# ATSAME70N20B register map
Vendor: Microchip Technology; Series: SAME70; File version: 0
CPU: CM7 r1p1, little endian, MPU, FPU, 3 interrupt priority bits
Registers are 32-bit, read-write, reset 0x0 unless marked. A register's access mark holds for its fields unless they carry their own. Offsets are from the block's base; [hi:lo] are bit positions; {n}, {i} and the like mark numbered series; 'fields as' and 'values as' point back to an identical list.

## USART0 — Universal Synchronous Asynchronous Receiver Transmitter
Base 0x40024000; register names take the prefix USART_
Same registers: USART1 0x40028000, USART2 0x4002C000
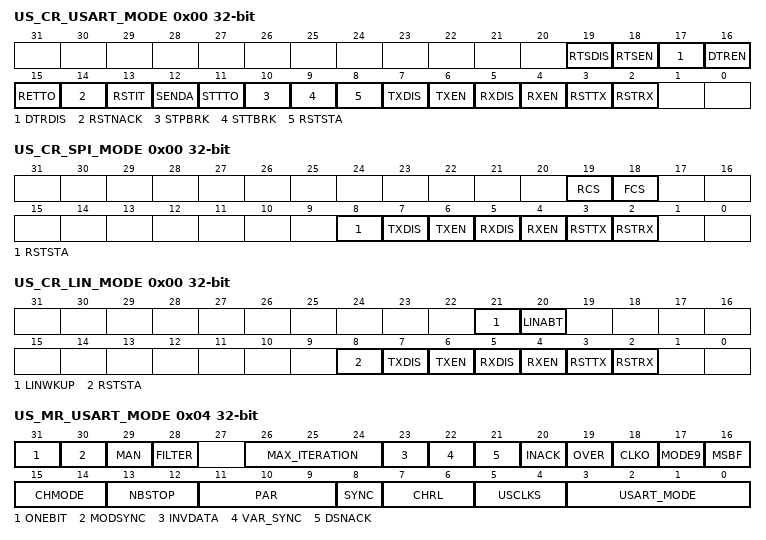
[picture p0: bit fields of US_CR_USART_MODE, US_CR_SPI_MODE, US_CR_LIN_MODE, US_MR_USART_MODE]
0x00 US_CR_USART_MODE wo — Control Register
  [19] RTSDIS — Request to Send Disable
  [18] RTSEN — Request to Send Enable
  [17] DTRDIS — Data Terminal Ready Disable
  [16] DTREN — Data Terminal Ready Enable
  [15] RETTO — Start Timeout Immediately
  [14] RSTNACK — Reset Non Acknowledge
  [13] RSTIT — Reset Iterations
  [12] SENDA — Send Address
  [11] STTTO — Clear TIMEOUT Flag and Start Timeout After Next Character Received
  [10] STPBRK — Stop Break
  [9] STTBRK — Start Break
  [8] RSTSTA — Reset Status Bits
  [7] TXDIS — Transmitter Disable
  [6] TXEN — Transmitter Enable
  [5] RXDIS — Receiver Disable
  [4] RXEN — Receiver Enable
  [3] RSTTX — Reset Transmitter
  [2] RSTRX — Reset Receiver
0x00 US_CR_SPI_MODE wo (alternate view of US_CR_USART_MODE) — Control Register
  [19] RCS — Release SPI Chip Select
  [18] FCS — Force SPI Chip Select
  [8] RSTSTA — Reset Status Bits
  [7] TXDIS — Transmitter Disable
  [6] TXEN — Transmitter Enable
  [5] RXDIS — Receiver Disable
  [4] RXEN — Receiver Enable
  [3] RSTTX — Reset Transmitter
  [2] RSTRX — Reset Receiver
0x00 US_CR_LIN_MODE wo (alternate view of US_CR_USART_MODE) — Control Register
  [21] LINWKUP — Send LIN Wakeup Signal
  [20] LINABT — Abort LIN Transmission
  [8] RSTSTA — Reset Status Bits
  [7] TXDIS — Transmitter Disable
  [6] TXEN — Transmitter Enable
  [5] RXDIS — Receiver Disable
  [4] RXEN — Receiver Enable
  [3] RSTTX — Reset Transmitter
  [2] RSTRX — Reset Receiver
0x04 US_MR_USART_MODE — Mode Register
  [31] ONEBIT — Start Frame Delimiter Selector
  [30] MODSYNC — Manchester Synchronization Mode
  [29] MAN — Manchester Encoder/Decoder Enable
  [28] FILTER — Receive Line Filter
  [26:24] MAX_ITERATION — Maximum Number of Automatic Iteration
  [23] INVDATA — Inverted Data
  [22] VAR_SYNC — Variable Synchronization of Command/Data Sync Start Frame Delimiter
  [21] DSNACK — Disable Successive NACK
  [20] INACK — Inhibit Non Acknowledge
  [19] OVER — Oversampling Mode
  [18] CLKO — Clock Output Select
  [17] MODE9 — 9-bit Character Length
  [16] MSBF — Bit Order
  [15:14] CHMODE — Channel Mode
    0=NORMAL (Normal mode); 1=AUTOMATIC (Automatic Echo. Receiver input is connected to the TXD pin.); 2=LOCAL_LOOPBACK (Local Loopback. Transmitter output is connected to the Receiver Input.); 3=REMOTE_LOOPBACK (Remote Loopback. RXD pin is internally connected to the TXD pin.)
  [13:12] NBSTOP — Number of Stop Bits
    0=_1_BIT (1 stop bit); 1=_1_5_BIT (1.5 stop bit (SYNC = 0) or reserved (SYNC = 1)); 2=_2_BIT (2 stop bits)
  [11:9] PAR — Parity Type
    0=EVEN (Even parity); 1=ODD (Odd parity); 2=SPACE (Parity forced to 0 (Space)); 3=MARK (Parity forced to 1 (Mark)); 4=NO (No parity); 6=MULTIDROP (Multidrop mode)
  [8] SYNC — Synchronous Mode Select
  [7:6] CHRL — Character Length
    {v}=_{v+5}_BIT (Character length is {v+5} bits) (v=0..3)
  [5:4] USCLKS — Clock Selection
    0=MCK (Peripheral clock is selected); 1=DIV (Peripheral clock divided (DIV = 8) is selected); 2=PCK (PMC programmable clock (PCK) is selected. If the SCK pin is driven (CLKO = 1), the CD field must be greater than 1.); 3=SCK (Serial clock (SCK) is selected)
  [3:0] USART_MODE — USART Mode of Operation
    0=NORMAL (Normal mode); 1=RS485; 2=HW_HANDSHAKING (Hardware handshaking); 3=MODEM; 4=IS07816_T_0 (IS07816 Protocol: T = 0); 6=IS07816_T_1 (IS07816 Protocol: T = 1); 8=IRDA; 9=LON; 10=LIN_MASTER (LIN Master mode); 11=LIN_SLAVE (LIN Slave mode); 14=SPI_MASTER (SPI Master mode (CLKO must be written to 1 and USCLKS = 0, 1 or 2)); 15=SPI_SLAVE (SPI Slave mode)
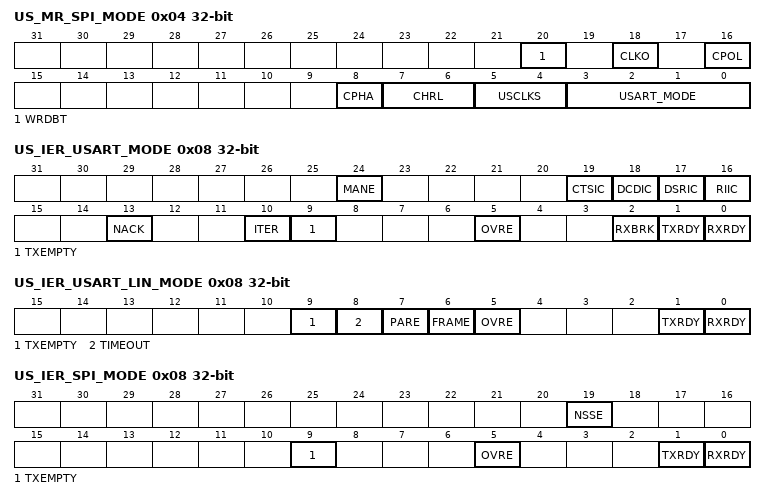
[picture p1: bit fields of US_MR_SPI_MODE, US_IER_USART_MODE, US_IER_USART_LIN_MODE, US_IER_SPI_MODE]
0x04 US_MR_SPI_MODE (alternate view of US_MR_USART_MODE) — Mode Register
  [20] WRDBT — Wait Read Data Before Transfer
  [18] CLKO — Clock Output Select
  [16] CPOL — SPI Clock Polarity
  [8] CPHA — SPI Clock Phase
  [7:6] CHRL — Character Length
    {v}=_{v+5}_BIT (Character length is {v+5} bits) (v=0..3)
  [5:4] USCLKS — Clock Selection
    values as US_MR_USART_MODE.USCLKS
  [3:0] USART_MODE — USART Mode of Operation
    values as US_MR_USART_MODE.USART_MODE
0x08 US_IER_USART_MODE wo — Interrupt Enable Register
  [24] MANE — Manchester Error Interrupt Enable
  [19] CTSIC — Clear to Send Input Change Interrupt Enable
  [18] DCDIC — Data Carrier Detect Input Change Interrupt Enable
  [17] DSRIC — Data Set Ready Input Change Enable
  [16] RIIC — Ring Indicator Input Change Enable
  [13] NACK — Non Acknowledge Interrupt Enable
  [10] ITER — Max number of Repetitions Reached Interrupt Enable
  [9] TXEMPTY — TXEMPTY Interrupt Enable
  [5] OVRE — Overrun Error Interrupt Enable
  [2] RXBRK — Receiver Break Interrupt Enable
  [1] TXRDY — TXRDY Interrupt Enable
  [0] RXRDY — RXRDY Interrupt Enable
0x08 US_IER_USART_LIN_MODE wo (alternate view of US_IER_USART_MODE) — Interrupt Enable Register
  [9] TXEMPTY — TXEMPTY Interrupt Enable
  [8] TIMEOUT — Timeout Interrupt Enable
  [7] PARE — Parity Error Interrupt Enable
  [6] FRAME — Framing Error Interrupt Enable
  [5] OVRE — Overrun Error Interrupt Enable
  [1] TXRDY — TXRDY Interrupt Enable
  [0] RXRDY — RXRDY Interrupt Enable
0x08 US_IER_SPI_MODE wo (alternate view of US_IER_USART_MODE) — Interrupt Enable Register
  [19] NSSE — NSS Line (Driving CTS Pin) Rising or Falling Edge Event
  [9] TXEMPTY — TXEMPTY Interrupt Enable
  [5] OVRE — Overrun Error Interrupt Enable
  [1] TXRDY — TXRDY Interrupt Enable
  [0] RXRDY — RXRDY Interrupt Enable
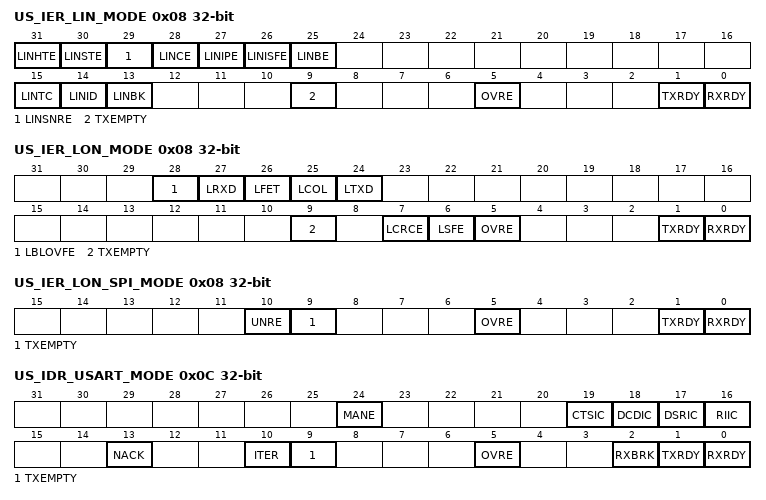
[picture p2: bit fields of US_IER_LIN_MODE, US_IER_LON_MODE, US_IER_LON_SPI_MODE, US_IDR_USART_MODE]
0x08 US_IER_LIN_MODE wo (alternate view of US_IER_USART_MODE) — Interrupt Enable Register
  [31] LINHTE — LIN Header Timeout Error Interrupt Enable
  [30] LINSTE — LIN Synch Tolerance Error Interrupt Enable
  [29] LINSNRE — LIN Slave Not Responding Error Interrupt Enable
  [28] LINCE — LIN Checksum Error Interrupt Enable
  [27] LINIPE — LIN Identifier Parity Interrupt Enable
  [26] LINISFE — LIN Inconsistent Synch Field Error Interrupt Enable
  [25] LINBE — LIN Bus Error Interrupt Enable
  [15] LINTC — LIN Transfer Completed Interrupt Enable
  [14] LINID — LIN Identifier Sent or LIN Identifier Received Interrupt Enable
  [13] LINBK — LIN Break Sent or LIN Break Received Interrupt Enable
  [9] TXEMPTY — TXEMPTY Interrupt Enable
  [5] OVRE — Overrun Error Interrupt Enable
  [1] TXRDY — TXRDY Interrupt Enable
  [0] RXRDY — RXRDY Interrupt Enable
0x08 US_IER_LON_MODE wo (alternate view of US_IER_USART_MODE) — Interrupt Enable Register
  [28] LBLOVFE — LON Backlog Overflow Error Interrupt Enable
  [27] LRXD — LON Reception Done Interrupt Enable
  [26] LFET — LON Frame Early Termination Interrupt Enable
  [25] LCOL — LON Collision Interrupt Enable
  [24] LTXD — LON Transmission Done Interrupt Enable
  [9] TXEMPTY — TXEMPTY Interrupt Enable
  [7] LCRCE — LON CRC Error Interrupt Enable
  [6] LSFE — LON Short Frame Error Interrupt Enable
  [5] OVRE — Overrun Error Interrupt Enable
  [1] TXRDY — TXRDY Interrupt Enable
  [0] RXRDY — RXRDY Interrupt Enable
0x08 US_IER_LON_SPI_MODE wo (alternate view of US_IER_USART_MODE) — Interrupt Enable Register
  [10] UNRE — Underrun Error Interrupt Enable
  [9] TXEMPTY — TXEMPTY Interrupt Enable
  [5] OVRE — Overrun Error Interrupt Enable
  [1] TXRDY — TXRDY Interrupt Enable
  [0] RXRDY — RXRDY Interrupt Enable
0x0C US_IDR_USART_MODE wo — Interrupt Disable Register
  [24] MANE — Manchester Error Interrupt Disable
  [19] CTSIC — Clear to Send Input Change Interrupt Disable
  [18] DCDIC — Data Carrier Detect Input Change Interrupt Disable
  [17] DSRIC — Data Set Ready Input Change Disable
  [16] RIIC — Ring Indicator Input Change Disable
  [13] NACK — Non Acknowledge Interrupt Disable
  [10] ITER — Max Number of Repetitions Reached Interrupt Disable
  [9] TXEMPTY — TXEMPTY Interrupt Disable
  [5] OVRE — Overrun Error Interrupt Enable
  [2] RXBRK — Receiver Break Interrupt Disable
  [1] TXRDY — TXRDY Interrupt Disable
  [0] RXRDY — RXRDY Interrupt Disable
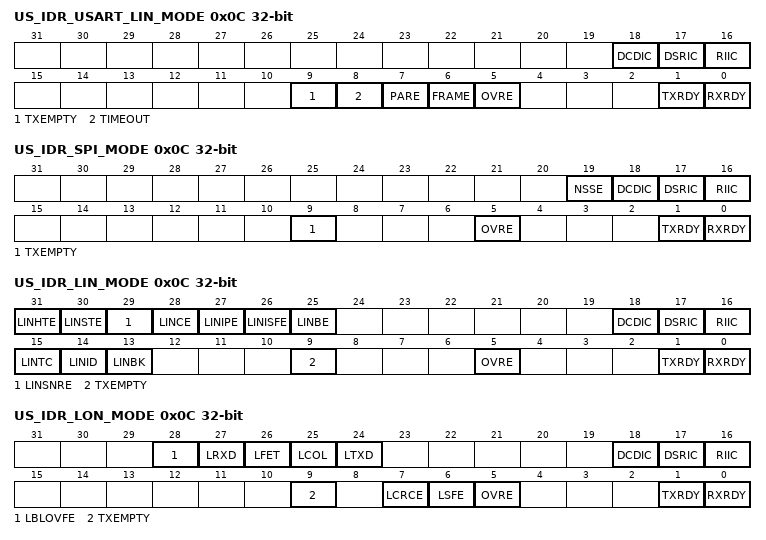
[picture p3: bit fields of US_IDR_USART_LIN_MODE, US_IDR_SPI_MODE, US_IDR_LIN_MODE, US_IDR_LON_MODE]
0x0C US_IDR_USART_LIN_MODE wo (alternate view of US_IDR_USART_MODE) — Interrupt Disable Register
  [18] DCDIC — Data Carrier Detect Input Change Interrupt Disable
  [17] DSRIC — Data Set Ready Input Change Disable
  [16] RIIC — Ring Indicator Input Change Disable
  [9] TXEMPTY — TXEMPTY Interrupt Disable
  [8] TIMEOUT — Timeout Interrupt Disable
  [7] PARE — Parity Error Interrupt Disable
  [6] FRAME — Framing Error Interrupt Disable
  [5] OVRE — Overrun Error Interrupt Enable
  [1] TXRDY — TXRDY Interrupt Disable
  [0] RXRDY — RXRDY Interrupt Disable
0x0C US_IDR_SPI_MODE wo (alternate view of US_IDR_USART_MODE) — Interrupt Disable Register
  [19] NSSE — NSS Line (Driving CTS Pin) Rising or Falling Edge Event
  [18] DCDIC — Data Carrier Detect Input Change Interrupt Disable
  [17] DSRIC — Data Set Ready Input Change Disable
  [16] RIIC — Ring Indicator Input Change Disable
  [9] TXEMPTY — TXEMPTY Interrupt Disable
  [5] OVRE — Overrun Error Interrupt Enable
  [1] TXRDY — TXRDY Interrupt Disable
  [0] RXRDY — RXRDY Interrupt Disable
0x0C US_IDR_LIN_MODE wo (alternate view of US_IDR_USART_MODE) — Interrupt Disable Register
  [31] LINHTE — LIN Header Timeout Error Interrupt Disable
  [30] LINSTE — LIN Synch Tolerance Error Interrupt Disable
  [29] LINSNRE — LIN Slave Not Responding Error Interrupt Disable
  [28] LINCE — LIN Checksum Error Interrupt Disable
  [27] LINIPE — LIN Identifier Parity Interrupt Disable
  [26] LINISFE — LIN Inconsistent Synch Field Error Interrupt Disable
  [25] LINBE — LIN Bus Error Interrupt Disable
  [18] DCDIC — Data Carrier Detect Input Change Interrupt Disable
  [17] DSRIC — Data Set Ready Input Change Disable
  [16] RIIC — Ring Indicator Input Change Disable
  [15] LINTC — LIN Transfer Completed Interrupt Disable
  [14] LINID — LIN Identifier Sent or LIN Identifier Received Interrupt Disable
  [13] LINBK — LIN Break Sent or LIN Break Received Interrupt Disable
  [9] TXEMPTY — TXEMPTY Interrupt Disable
  [5] OVRE — Overrun Error Interrupt Enable
  [1] TXRDY — TXRDY Interrupt Disable
  [0] RXRDY — RXRDY Interrupt Disable
0x0C US_IDR_LON_MODE wo (alternate view of US_IDR_USART_MODE) — Interrupt Disable Register
  [28] LBLOVFE — LON Backlog Overflow Error Interrupt Disable
  [27] LRXD — LON Reception Done Interrupt Disable
  [26] LFET — LON Frame Early Termination Interrupt Disable
  [25] LCOL — LON Collision Interrupt Disable
  [24] LTXD — LON Transmission Done Interrupt Disable
  [18] DCDIC — Data Carrier Detect Input Change Interrupt Disable
  [17] DSRIC — Data Set Ready Input Change Disable
  [16] RIIC — Ring Indicator Input Change Disable
  [9] TXEMPTY — TXEMPTY Interrupt Disable
  [7] LCRCE — LON CRC Error Interrupt Disable
  [6] LSFE — LON Short Frame Error Interrupt Disable
  [5] OVRE — Overrun Error Interrupt Enable
  [1] TXRDY — TXRDY Interrupt Disable
  [0] RXRDY — RXRDY Interrupt Disable
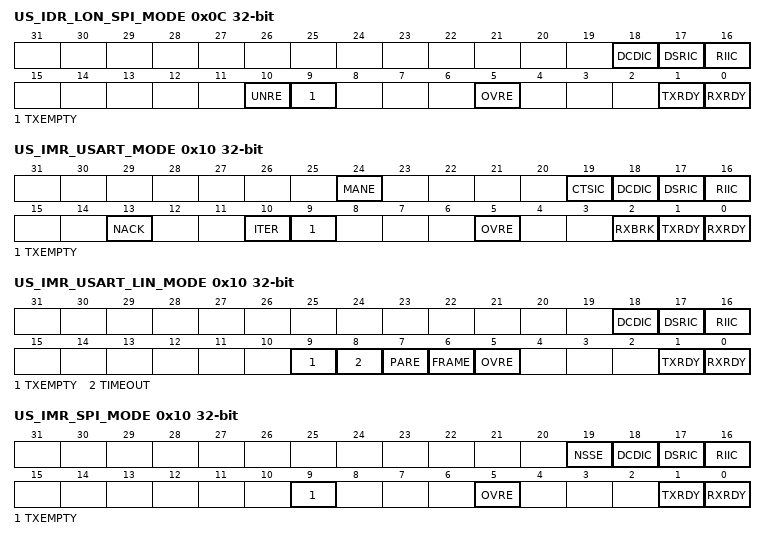
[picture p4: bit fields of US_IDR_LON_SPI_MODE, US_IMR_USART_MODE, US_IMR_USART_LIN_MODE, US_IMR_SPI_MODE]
0x0C US_IDR_LON_SPI_MODE wo (alternate view of US_IDR_USART_MODE) — Interrupt Disable Register
  [18] DCDIC — Data Carrier Detect Input Change Interrupt Disable
  [17] DSRIC — Data Set Ready Input Change Disable
  [16] RIIC — Ring Indicator Input Change Disable
  [10] UNRE — SPI Underrun Error Interrupt Disable
  [9] TXEMPTY — TXEMPTY Interrupt Disable
  [5] OVRE — Overrun Error Interrupt Enable
  [1] TXRDY — TXRDY Interrupt Disable
  [0] RXRDY — RXRDY Interrupt Disable
0x10 US_IMR_USART_MODE ro — Interrupt Mask Register
  [24] MANE — Manchester Error Interrupt Mask
  [19] CTSIC — Clear to Send Input Change Interrupt Mask
  [18] DCDIC — Data Carrier Detect Input Change Interrupt Mask
  [17] DSRIC — Data Set Ready Input Change Mask
  [16] RIIC — Ring Indicator Input Change Mask
  [13] NACK — Non Acknowledge Interrupt Mask
  [10] ITER — Max Number of Repetitions Reached Interrupt Mask
  [9] TXEMPTY — TXEMPTY Interrupt Mask
  [5] OVRE — Overrun Error Interrupt Mask
  [2] RXBRK — Receiver Break Interrupt Mask
  [1] TXRDY — TXRDY Interrupt Mask
  [0] RXRDY — RXRDY Interrupt Mask
0x10 US_IMR_USART_LIN_MODE ro (alternate view of US_IMR_USART_MODE) — Interrupt Mask Register
  [18] DCDIC — Data Carrier Detect Input Change Interrupt Mask
  [17] DSRIC — Data Set Ready Input Change Mask
  [16] RIIC — Ring Indicator Input Change Mask
  [9] TXEMPTY — TXEMPTY Interrupt Mask
  [8] TIMEOUT — Timeout Interrupt Mask
  [7] PARE — Parity Error Interrupt Mask
  [6] FRAME — Framing Error Interrupt Mask
  [5] OVRE — Overrun Error Interrupt Mask
  [1] TXRDY — TXRDY Interrupt Mask
  [0] RXRDY — RXRDY Interrupt Mask
0x10 US_IMR_SPI_MODE ro (alternate view of US_IMR_USART_MODE) — Interrupt Mask Register
  [19] NSSE — NSS Line (Driving CTS Pin) Rising or Falling Edge Event
  [18] DCDIC — Data Carrier Detect Input Change Interrupt Mask
  [17] DSRIC — Data Set Ready Input Change Mask
  [16] RIIC — Ring Indicator Input Change Mask
  [9] TXEMPTY — TXEMPTY Interrupt Mask
  [5] OVRE — Overrun Error Interrupt Mask
  [1] TXRDY — TXRDY Interrupt Mask
  [0] RXRDY — RXRDY Interrupt Mask
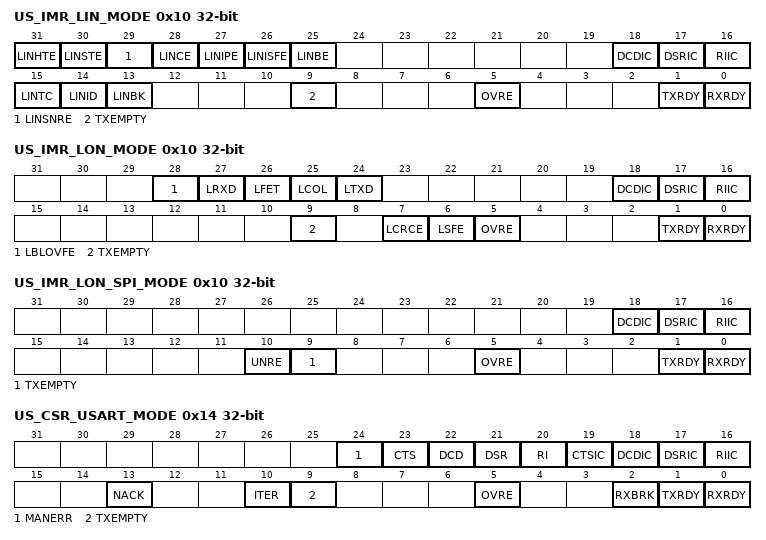
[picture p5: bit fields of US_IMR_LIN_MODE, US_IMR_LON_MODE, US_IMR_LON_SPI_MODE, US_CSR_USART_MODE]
0x10 US_IMR_LIN_MODE ro (alternate view of US_IMR_USART_MODE) — Interrupt Mask Register
  [31] LINHTE — LIN Header Timeout Error Interrupt Mask
  [30] LINSTE — LIN Synch Tolerance Error Interrupt Mask
  [29] LINSNRE — LIN Slave Not Responding Error Interrupt Mask
  [28] LINCE — LIN Checksum Error Interrupt Mask
  [27] LINIPE — LIN Identifier Parity Interrupt Mask
  [26] LINISFE — LIN Inconsistent Synch Field Error Interrupt Mask
  [25] LINBE — LIN Bus Error Interrupt Mask
  [18] DCDIC — Data Carrier Detect Input Change Interrupt Mask
  [17] DSRIC — Data Set Ready Input Change Mask
  [16] RIIC — Ring Indicator Input Change Mask
  [15] LINTC — LIN Transfer Completed Interrupt Mask
  [14] LINID — LIN Identifier Sent or LIN Identifier Received Interrupt Mask
  [13] LINBK — LIN Break Sent or LIN Break Received Interrupt Mask
  [9] TXEMPTY — TXEMPTY Interrupt Mask
  [5] OVRE — Overrun Error Interrupt Mask
  [1] TXRDY — TXRDY Interrupt Mask
  [0] RXRDY — RXRDY Interrupt Mask
0x10 US_IMR_LON_MODE ro (alternate view of US_IMR_USART_MODE) — Interrupt Mask Register
  [28] LBLOVFE — LON Backlog Overflow Error Interrupt Mask
  [27] LRXD — LON Reception Done Interrupt Mask
  [26] LFET — LON Frame Early Termination Interrupt Mask
  [25] LCOL — LON Collision Interrupt Mask
  [24] LTXD — LON Transmission Done Interrupt Mask
  [18] DCDIC — Data Carrier Detect Input Change Interrupt Mask
  [17] DSRIC — Data Set Ready Input Change Mask
  [16] RIIC — Ring Indicator Input Change Mask
  [9] TXEMPTY — TXEMPTY Interrupt Mask
  [7] LCRCE — LON CRC Error Interrupt Mask
  [6] LSFE — LON Short Frame Error Interrupt Mask
  [5] OVRE — Overrun Error Interrupt Mask
  [1] TXRDY — TXRDY Interrupt Mask
  [0] RXRDY — RXRDY Interrupt Mask
0x10 US_IMR_LON_SPI_MODE ro (alternate view of US_IMR_USART_MODE) — Interrupt Mask Register
  [18] DCDIC — Data Carrier Detect Input Change Interrupt Mask
  [17] DSRIC — Data Set Ready Input Change Mask
  [16] RIIC — Ring Indicator Input Change Mask
  [10] UNRE — SPI Underrun Error Interrupt Mask
  [9] TXEMPTY — TXEMPTY Interrupt Mask
  [5] OVRE — Overrun Error Interrupt Mask
  [1] TXRDY — TXRDY Interrupt Mask
  [0] RXRDY — RXRDY Interrupt Mask
0x14 US_CSR_USART_MODE ro — Channel Status Register
  [24] MANERR — Manchester Error (cleared by writing a one to the bit US_CR.RSTSTA)
  [23] CTS — Image of CTS Input
  [22] DCD — Image of DCD Input
  [21] DSR — Image of DSR Input
  [20] RI — Image of RI Input
  [19] CTSIC — Clear to Send Input Change Flag (cleared on read)
  [18] DCDIC — Data Carrier Detect Input Change Flag (cleared on read)
  [17] DSRIC — Data Set Ready Input Change Flag (cleared on read)
  [16] RIIC — Ring Indicator Input Change Flag (cleared on read)
  [13] NACK — Non Acknowledge Interrupt (cleared by writing a one to bit US_CR.RSTNACK)
  [10] ITER — Max Number of Repetitions Reached (cleared by writing a one to bit US_CR.RSTIT)
  [9] TXEMPTY — Transmitter Empty (cleared by writing US_THR)
  [5] OVRE — Overrun Error (cleared by writing a one to bit US_CR.RSTSTA)
  [2] RXBRK — Break Received/End of Break (cleared by writing a one to bit US_CR.RSTSTA)
  [1] TXRDY — Transmitter Ready (cleared by writing US_THR)
  [0] RXRDY — Receiver Ready (cleared by reading US_RHR)
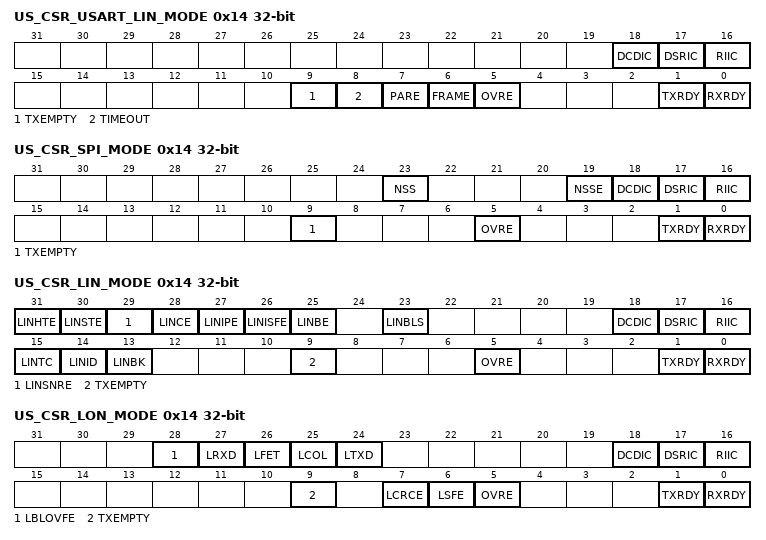
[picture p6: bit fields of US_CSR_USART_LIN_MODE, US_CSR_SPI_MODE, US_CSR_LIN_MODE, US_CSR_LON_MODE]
0x14 US_CSR_USART_LIN_MODE ro (alternate view of US_CSR_USART_MODE) — Channel Status Register
  [18] DCDIC — Data Carrier Detect Input Change Flag (cleared on read)
  [17] DSRIC — Data Set Ready Input Change Flag (cleared on read)
  [16] RIIC — Ring Indicator Input Change Flag (cleared on read)
  [9] TXEMPTY — Transmitter Empty (cleared by writing US_THR)
  [8] TIMEOUT — Receiver Timeout (cleared by writing a one to bit US_CR.STTTO)
  [7] PARE — Parity Error (cleared by writing a one to bit US_CR.RSTSTA)
  [6] FRAME — Framing Error (cleared by writing a one to bit US_CR.RSTSTA)
  [5] OVRE — Overrun Error (cleared by writing a one to bit US_CR.RSTSTA)
  [1] TXRDY — Transmitter Ready (cleared by writing US_THR)
  [0] RXRDY — Receiver Ready (cleared by reading US_RHR)
0x14 US_CSR_SPI_MODE ro (alternate view of US_CSR_USART_MODE) — Channel Status Register
  [23] NSS — Image of NSS Line
  [19] NSSE — NSS Line (Driving CTS Pin) Rising or Falling Edge Event
  [18] DCDIC — Data Carrier Detect Input Change Flag (cleared on read)
  [17] DSRIC — Data Set Ready Input Change Flag (cleared on read)
  [16] RIIC — Ring Indicator Input Change Flag (cleared on read)
  [9] TXEMPTY — Transmitter Empty (cleared by writing US_THR)
  [5] OVRE — Overrun Error (cleared by writing a one to bit US_CR.RSTSTA)
  [1] TXRDY — Transmitter Ready (cleared by writing US_THR)
  [0] RXRDY — Receiver Ready (cleared by reading US_RHR)
0x14 US_CSR_LIN_MODE ro (alternate view of US_CSR_USART_MODE) — Channel Status Register
  [31] LINHTE — LIN Header Timeout Error
  [30] LINSTE — LIN Synch Tolerance Error
  [29] LINSNRE — LIN Slave Not Responding Error Interrupt Mask
  [28] LINCE — LIN Checksum Error
  [27] LINIPE — LIN Identifier Parity Error
  [26] LINISFE — LIN Inconsistent Synch Field Error
  [25] LINBE — LIN Bus Error
  [23] LINBLS — LIN Bus Line Status
  [18] DCDIC — Data Carrier Detect Input Change Flag (cleared on read)
  [17] DSRIC — Data Set Ready Input Change Flag (cleared on read)
  [16] RIIC — Ring Indicator Input Change Flag (cleared on read)
  [15] LINTC — LIN Transfer Completed
  [14] LINID — LIN Identifier Sent or LIN Identifier Received
  [13] LINBK — LIN Break Sent or LIN Break Received
  [9] TXEMPTY — Transmitter Empty (cleared by writing US_THR)
  [5] OVRE — Overrun Error (cleared by writing a one to bit US_CR.RSTSTA)
  [1] TXRDY — Transmitter Ready (cleared by writing US_THR)
  [0] RXRDY — Receiver Ready (cleared by reading US_RHR)
0x14 US_CSR_LON_MODE ro (alternate view of US_CSR_USART_MODE) — Channel Status Register
  [28] LBLOVFE — LON Backlog Overflow Error
  [27] LRXD — LON Reception End Flag
  [26] LFET — LON Frame Early Termination
  [25] LCOL — LON Collision Detected Flag
  [24] LTXD — LON Transmission End Flag
  [18] DCDIC — Data Carrier Detect Input Change Flag (cleared on read)
  [17] DSRIC — Data Set Ready Input Change Flag (cleared on read)
  [16] RIIC — Ring Indicator Input Change Flag (cleared on read)
  [9] TXEMPTY — Transmitter Empty (cleared by writing US_THR)
  [7] LCRCE — LON CRC Error
  [6] LSFE — LON Short Frame Error
  [5] OVRE — Overrun Error (cleared by writing a one to bit US_CR.RSTSTA)
  [1] TXRDY — Transmitter Ready (cleared by writing US_THR)
  [0] RXRDY — Receiver Ready (cleared by reading US_RHR)
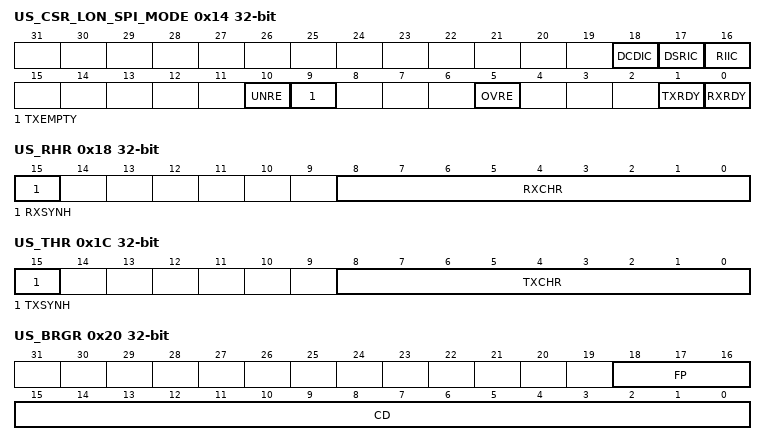
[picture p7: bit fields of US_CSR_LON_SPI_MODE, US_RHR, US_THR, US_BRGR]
0x14 US_CSR_LON_SPI_MODE ro (alternate view of US_CSR_USART_MODE) — Channel Status Register
  [18] DCDIC — Data Carrier Detect Input Change Flag (cleared on read)
  [17] DSRIC — Data Set Ready Input Change Flag (cleared on read)
  [16] RIIC — Ring Indicator Input Change Flag (cleared on read)
  [10] UNRE — SPI Underrun Error
  [9] TXEMPTY — Transmitter Empty (cleared by writing US_THR)
  [5] OVRE — Overrun Error (cleared by writing a one to bit US_CR.RSTSTA)
  [1] TXRDY — Transmitter Ready (cleared by writing US_THR)
  [0] RXRDY — Receiver Ready (cleared by reading US_RHR)
0x18 US_RHR ro — Receive Holding Register
  [15] RXSYNH — Received Sync
  [8:0] RXCHR — Received Character
0x1C US_THR wo — Transmit Holding Register
  [15] TXSYNH — Sync Field to be Transmitted
  [8:0] TXCHR — Character to be Transmitted
0x20 US_BRGR — Baud Rate Generator Register
  [18:16] FP — Fractional Part
  [15:0] CD — Clock Divider
0x24 US_RTOR — Receiver Timeout Register
  [16:0] TO — Timeout Value
0x28 US_TTGR_USART_MODE — Transmitter Timeguard Register
  [7:0] TG — Timeguard Value
0x28 US_TTGR_LON_MODE (alternate view of US_TTGR_USART_MODE) — Transmitter Timeguard Register
  [23:0] PCYCLE — LON PCYCLE Length
0x40 US_FIDI_USART_MODE — FI DI Ratio Register
  [15:0] FI_DI_RATIO — FI Over DI Ratio Value
0x40 US_FIDI_LON_MODE (alternate view of US_FIDI_USART_MODE) — FI DI Ratio Register
  [23:0] BETA2 — LON BETA2 Length
0x44 US_NER ro — Number of Errors Register
  [7:0] NB_ERRORS — Number of Errors
0x4C US_IF — IrDA Filter Register
  [7:0] IRDA_FILTER
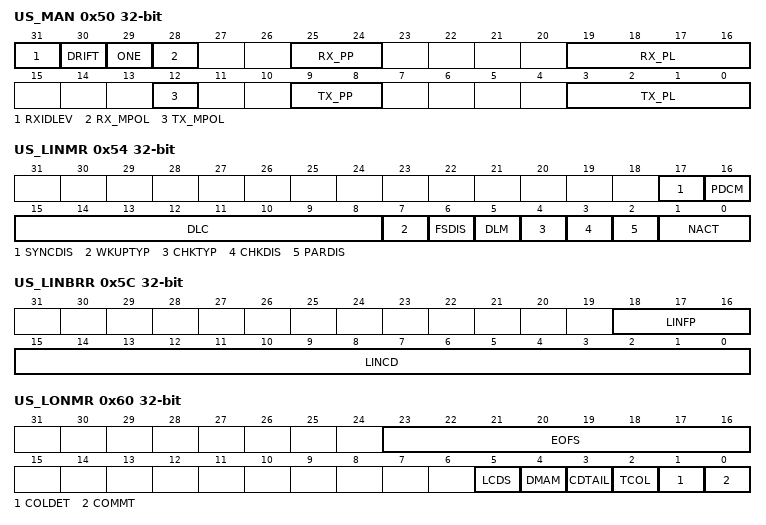
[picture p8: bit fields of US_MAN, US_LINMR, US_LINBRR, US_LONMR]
0x50 US_MAN — Manchester Configuration Register
  [31] RXIDLEV — Receiver Idle Value
  [30] DRIFT — Drift Compensation
  [29] ONE — Must Be Set to 1
  [28] RX_MPOL — Receiver Manchester Polarity
  [25:24] RX_PP — Receiver Preamble Pattern detected
    0=ALL_ONE (The preamble is composed of '1's); 1=ALL_ZERO (The preamble is composed of '0's); 2=ZERO_ONE (The preamble is composed of '01's); 3=ONE_ZERO (The preamble is composed of '10's)
  [19:16] RX_PL — Receiver Preamble Length
  [12] TX_MPOL — Transmitter Manchester Polarity
  [9:8] TX_PP — Transmitter Preamble Pattern
    values as RX_PP
  [3:0] TX_PL — Transmitter Preamble Length
0x54 US_LINMR — LIN Mode Register
  [17] SYNCDIS — Synchronization Disable
  [16] PDCM — DMAC Mode
  [15:8] DLC — Data Length Control
  [7] WKUPTYP — Wakeup Signal Type
  [6] FSDIS — Frame Slot Mode Disable
  [5] DLM — Data Length Mode
  [4] CHKTYP — Checksum Type
  [3] CHKDIS — Checksum Disable
  [2] PARDIS — Parity Disable
  [1:0] NACT — LIN Node Action
    0=PUBLISH (The USART transmits the response.); 1=SUBSCRIBE (The USART receives the response.); 2=IGNORE (The USART does not transmit and does not receive the response.)
0x58 US_LINIR — LIN Identifier Register
  [7:0] IDCHR — Identifier Character
0x5C US_LINBRR ro — LIN Baud Rate Register
  [18:16] LINFP — Fractional Part after Synchronization
  [15:0] LINCD — Clock Divider after Synchronization
0x60 US_LONMR — LON Mode Register
  [23:16] EOFS — End of Frame Condition Size
  [5] LCDS — LON Collision Detection Source
  [4] DMAM — LON DMA Mode
  [3] CDTAIL — LON Collision Detection on Frame Tail
  [2] TCOL — Terminate Frame upon Collision Notification
  [1] COLDET — LON Collision Detection Feature
  [0] COMMT — LON comm_type Parameter Value
0x64 US_LONPR — LON Preamble Register
  [13:0] LONPL — LON Preamble Length
0x68 US_LONDL — LON Data Length Register
  [7:0] LONDL — LON Data Length
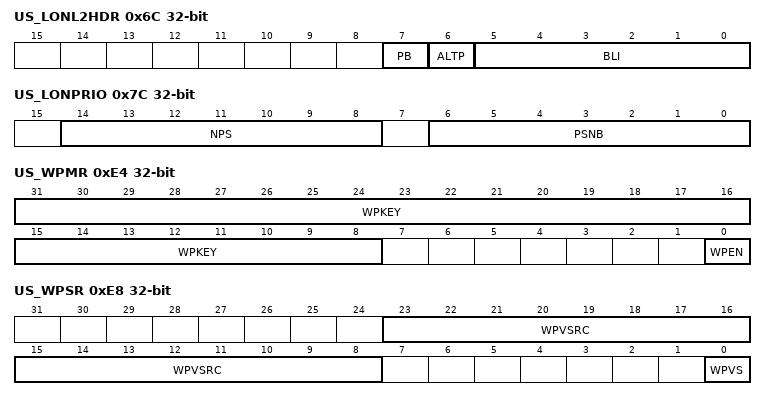
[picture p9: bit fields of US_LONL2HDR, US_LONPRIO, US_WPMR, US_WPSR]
0x6C US_LONL2HDR — LON L2HDR Register
  [7] PB — LON Priority Bit
  [6] ALTP — LON Alternate Path Bit
  [5:0] BLI — LON Backlog Increment
0x70 US_LONBL ro — LON Backlog Register
  [5:0] LONBL — LON Node Backlog Value
0x74 US_LONB1TX — LON Beta1 Tx Register
  [23:0] BETA1TX — LON Beta1 Length after Transmission
0x78 US_LONB1RX — LON Beta1 Rx Register
  [23:0] BETA1RX — LON Beta1 Length after Reception
0x7C US_LONPRIO — LON Priority Register
  [14:8] NPS — LON Node Priority Slot
  [6:0] PSNB — LON Priority Slot Number
0x80 US_IDTTX — LON IDT Tx Register
  [23:0] IDTTX — LON Indeterminate Time after Transmission (comm_type = 1 mode only)
0x84 US_IDTRX — LON IDT Rx Register
  [23:0] IDTRX — LON Indeterminate Time after Reception (comm_type = 1 mode only)
0x88 US_ICDIFF — IC DIFF Register
  [3:0] ICDIFF — IC Differentiator Number
0xE4 US_WPMR — Write Protection Mode Register
  [31:8] WPKEY — Write Protection Key
    0x555341=PASSWD (Writing any other value in this field aborts the write operation of the WPEN bit. Always reads as 0.)
  [0] WPEN — Write Protection Enable
0xE8 US_WPSR ro — Write Protection Status Register
  [23:8] WPVSRC — Write Protection Violation Source
  [0] WPVS — Write Protection Violation Status

## Notices in the file
Copyright (c) 2017 Microchip Technology Inc.
SPDX-License-Identifier: Apache-2.0
Licensed under the Apache License, Version 2.0 (the "License");
you may not use this file except in compliance with the License.
You may obtain a copy of the License at
http://www.apache.org/licenses/LICENSE-2.0
Unless required by applicable law or agreed to in writing, software
distributed under the License is distributed on an "AS IS" BASIS,
WITHOUT WARRANTIES OR CONDITIONS OF ANY KIND, either express or implied.
See the License for the specific language governing permissions and
limitations under the License.
